VERSION ""

NS_ :

BS_:

BU_: XXX

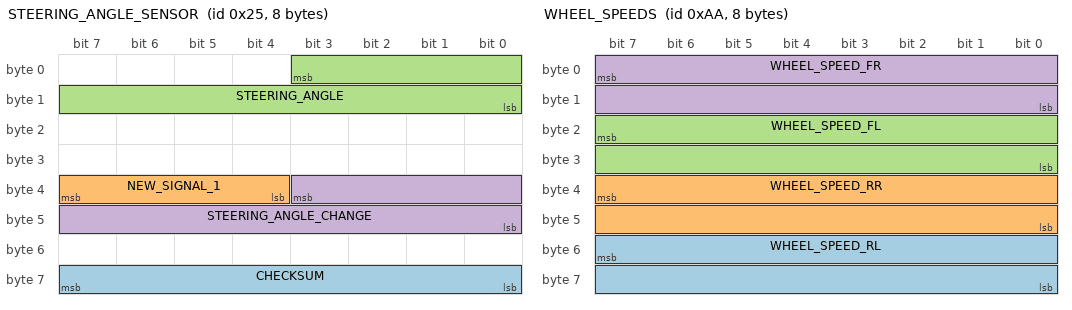
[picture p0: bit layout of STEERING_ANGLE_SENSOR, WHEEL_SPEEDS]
BO_ 37 STEERING_ANGLE_SENSOR: 8 XXX
 SG_ CHECKSUM : 63|8@0- (1,0) [0|255] "" XXX
 SG_ NEW_SIGNAL_1 : 39|4@0- (1,0) [0|15] "" XXX
 SG_ STEERING_ANGLE : 3|12@0- (1,1) [-670|670] "deg" XXX
 SG_ STEERING_ANGLE_CHANGE : 35|12@0- (1,0) [0|65535] "deg/s" XXX

BO_ 740 STEERING_LKA: 8 XXX
 SG_ COUNTER : 6|6@0+ (1,0) [0|15] "" XXX
 SG_ CHECKSUM : 32|8@1+ (1,0) [0|255] "" XXX

BO_ 36 YAW_RATE_SENSOR: 8 XXX
 SG_ YAW_RATE : 1|10@0+ (0.244,-124.2) [0|255] "" XXX
 SG_ NEW_SIGNAL_2 : 17|10@0+ (1,0) [0|1023] "" XXX

BO_ 170 WHEEL_SPEEDS: 8 XXX
 SG_ WHEEL_SPEED_RL : 55|16@0+ (0,-67.67) [0|65535] "" XXX
 SG_ WHEEL_SPEED_RR : 39|16@0+ (0,-67.67) [0|65535] "" XXX
 SG_ WHEEL_SPEED_FL : 23|16@0+ (0,-67.67) [0|65535] "" XXX
 SG_ WHEEL_SPEED_FR : 7|16@0+ (0.01,-67.67) [0|65535] "" XXX

BO_ 452 ENGINE_RPM: 8 XXX
 SG_ RPM : 7|16@0- (0,0) [0|65535] "rpm" XXX

BO_ 1043 TIME: 8 XXX
 SG_ MINUTE : 39|8@0+ (1,0) [0|255] "minute" XXX

VAL_ 37 STEERING_ANGLE_CHANGE Difference "between" 2 "transmitted" position "values" in "succession." ;
